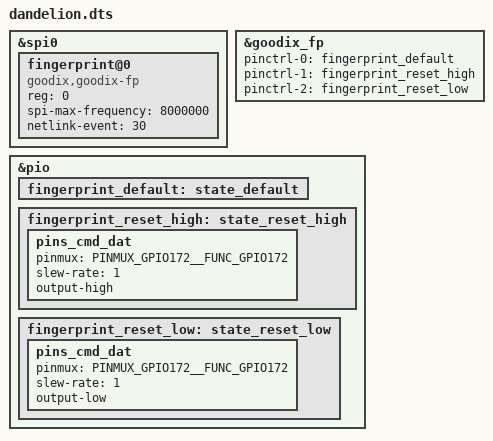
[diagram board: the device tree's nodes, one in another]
/*
 * Copyright (C) 2019 MediaTek Inc.
 * Copyright (C) 2021 XiaoMi, Inc.
 *
 * This program is free software; you can redistribute it and/or modify
 * it under the terms of the GNU General Public License version 2 as
 * published by the Free Software Foundation.
 *
 * This program is distributed in the hope that it will be useful,
 * but WITHOUT ANY WARRANTY; without even the implied warranty of
 * MERCHANTABILITY or FITNESS FOR A PARTICULAR PURPOSE.
 * See http://www.gnu.org/licenses/gpl-2.0.html for more details.
 */

#include "custom_common.dtsi"
#include "touchscreen.dtsi"
#include <dandelion/cust.dtsi>

/* FINGERPRINT start */
&spi0 {
	#address-cells = <1>;
	#size-cells = <0>;
	fingerprint@0 {
		compatible = "goodix,goodix-fp";
		reg = <0>;
		spi-max-frequency = <8000000>;
		netlink-event = <30>;
		status = "okay";
	};
};

&goodix_fp {
	pinctrl-names = "default", "reset_high", "reset_low";
	pinctrl-0 = <&fingerprint_default>;
	pinctrl-1 = <&fingerprint_reset_high>;
	pinctrl-2 = <&fingerprint_reset_low>;
	status = "okay";
};

&pio {
	fingerprint_default: state_default {
	};
	fingerprint_reset_high: state_reset_high {
		pins_cmd_dat {
			pinmux = <PINMUX_GPIO172__FUNC_GPIO172>;
			slew-rate = <1>;
			output-high;
		};
	};
	fingerprint_reset_low: state_reset_low {
		pins_cmd_dat {
			pinmux = <PINMUX_GPIO172__FUNC_GPIO172>;
			slew-rate = <1>;
			output-low;
		};
	};
};
/* FINGERPRINT end */
